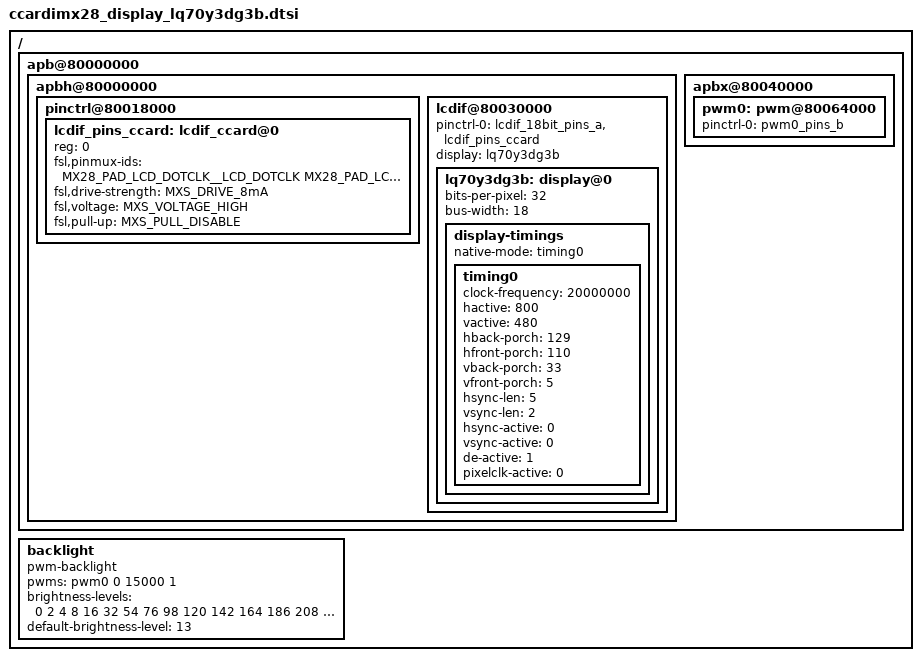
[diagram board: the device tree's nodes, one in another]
/*
 * Copyright 2013 Digi International, Inc.
 *
 * The code contained herein is licensed under the GNU General Public
 * License. You may obtain a copy of the GNU General Public License
 * Version 2 or later at the following locations:
 *
 * http://www.opensource.org/licenses/gpl-license.html
 * http://www.gnu.org/copyleft/gpl.html
 */

/ {
	apb@80000000 {
		apbh@80000000 {
			pinctrl@80018000 {
				lcdif_pins_ccard: lcdif_ccard@0 {
					reg = <0>;
					fsl,pinmux-ids = <
						MX28_PAD_LCD_DOTCLK__LCD_DOTCLK
						MX28_PAD_LCD_ENABLE__LCD_ENABLE
						MX28_PAD_LCD_RESET__LCD_VSYNC
						MX28_PAD_LCD_HSYNC__LCD_HSYNC
					>;
					fsl,drive-strength = <MXS_DRIVE_8mA>;
					fsl,voltage = <MXS_VOLTAGE_HIGH>;
					fsl,pull-up = <MXS_PULL_DISABLE>;
				};
			};

			lcdif@80030000 {
				pinctrl-names = "default";
				pinctrl-0 = <&lcdif_18bit_pins_a
					     &lcdif_pins_ccard>;
				display = <&lq70y3dg3b>;
				status = "okay";

				/* Sharp LQ70Y3DG3B */
				lq70y3dg3b: display@0 {
                                       bits-per-pixel = <32>;
                                       bus-width = <18>;

                                       display-timings {
						native-mode = <&timing0>;
						timing0: timing0 {
							clock-frequency = <20000000>;
							hactive = <800>;
							vactive = <480>;
							hback-porch = <129>;
							hfront-porch = <110>;
							vback-porch = <33>;
							vfront-porch = <5>;
							hsync-len = <5>;
							vsync-len = <2>;
							hsync-active = <0>;
							vsync-active = <0>;
							de-active = <1>;
							pixelclk-active = <0>;
						};
                                       };
				};
			};
		};

		apbx@80040000 {
			pwm0: pwm@80064000 {
				pinctrl-names = "default";
				pinctrl-0 = <&pwm0_pins_b>;
				status = "okay";
			};
		};
	};

	backlight {
		compatible = "pwm-backlight";
		pwms = <&pwm0 0 15000 1>;	/* inverted duty */
		brightness-levels = <0 2 4 8 16 32 54 76 98
				     120 142 164 186 208 230 255>;
		default-brightness-level = <13>;
		status = "okay";
	};
};
